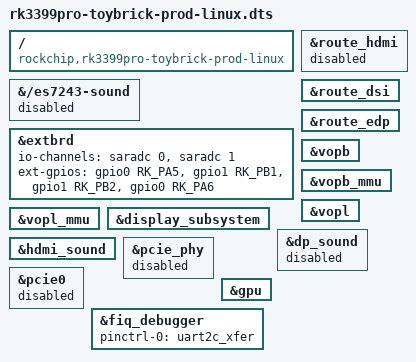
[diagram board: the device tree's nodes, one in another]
/*
 * Copyright (c) 2019 Fuzhou Rockchip Electronics Co., Ltd
 *
 * This file is dual-licensed: you can use it either under the terms
 * of the GPL or the X11 license, at your option. Note that this dual
 * licensing only applies to this file, and not this project as a
 * whole.
 *
 *  a) This file is free software; you can redistribute it and/or
 *     modify it under the terms of the GNU General Public License as
 *     published by the Free Software Foundation; either version 2 of the
 *     License, or (at your option) any later version.
 *
 *     This file is distributed in the hope that it will be useful,
 *     but WITHOUT ANY WARRANTY; without even the implied warranty of
 *     MERCHANTABILITY or FITNESS FOR A PARTICULAR PURPOSE.  See the
 *     GNU General Public License for more details.
 *
 * Or, alternatively,
 *
 *  b) Permission is hereby granted, free of charge, to any person
 *     obtaining a copy of this software and associated documentation
 *     files (the "Software"), to deal in the Software without
 *     restriction, including without limitation the rights to use,
 *     copy, modify, merge, publish, distribute, sublicense, and/or
 *     sell copies of the Software, and to permit persons to whom the
 *     Software is furnished to do so, subject to the following
 *     conditions:
 *
 *     The above copyright notice and this permission notice shall be
 *     included in all copies or substantial portions of the Software.
 *
 *     THE SOFTWARE IS PROVIDED "AS IS", WITHOUT WARRANTY OF ANY KIND,
 *     EXPRESS OR IMPLIED, INCLUDING BUT NOT LIMITED TO THE WARRANTIES
 *     OF MERCHANTABILITY, FITNESS FOR A PARTICULAR PURPOSE AND
 *     NONINFRINGEMENT. IN NO EVENT SHALL THE AUTHORS OR COPYRIGHT
 *     HOLDERS BE LIABLE FOR ANY CLAIM, DAMAGES OR OTHER LIABILITY,
 *     WHETHER IN AN ACTION OF CONTRACT, TORT OR OTHERWISE, ARISING
 *     FROM, OUT OF OR IN CONNECTION WITH THE SOFTWARE OR THE USE OR
 *     OTHER DEALINGS IN THE SOFTWARE.
 */

/dts-v1/;
#include "rk3399pro-toybrick-prod.dtsi"
#include "rk3399-linux.dtsi"
#include "rk3399pro-toybrick-extboard.dtsi"

/delete-node/ &drm_logo;
/delete-node/ &ramoops_mem;
/delete-node/ &ramoops;

/ {
	compatible = "rockchip,rk3399pro-toybrick-prod-linux","rockchip,rk3399pro";
};

&{/es7243-sound} {
	status = "disabled";
};

&extbrd {
	status = "okay";
	io-channels = <&saradc 0>, <&saradc 1>;
	ext-gpios = <&gpio0 RK_PA5 GPIO_ACTIVE_HIGH>,    /* GPIO0_A5 */
		   <&gpio1 RK_PB1 GPIO_ACTIVE_HIGH>,    /* GPIO1_B1 */
		   <&gpio1 RK_PB2 GPIO_ACTIVE_HIGH>,    /* GPIO1_B2 */
		   <&gpio0 RK_PA6 GPIO_ACTIVE_HIGH>;    /* GPIO0_A6 */
};

&route_hdmi {
        status = "disabled";
};

&route_dsi {
        status = "okay";
};

&route_edp {
        status = "okay";
};

&vopb {
	status = "okay";
};

&vopb_mmu {
	status = "okay";
};

&vopl {
	status = "okay";
};

&vopl_mmu {
	status = "okay";
};

&display_subsystem {
	status = "okay";
	/delete-property/ logo-memory-region;
};

&dp_sound {
        status = "disabled";
};

&hdmi_sound {
        status = "okay";
};

&pcie_phy {
	status = "disabled";
};

&pcie0 {
	status = "disabled";
};

&gpu {
	interrupt-names = "JOB", "MMU", "GPU";
};

&fiq_debugger {
        pinctrl-0 = <&uart2c_xfer>;
};
